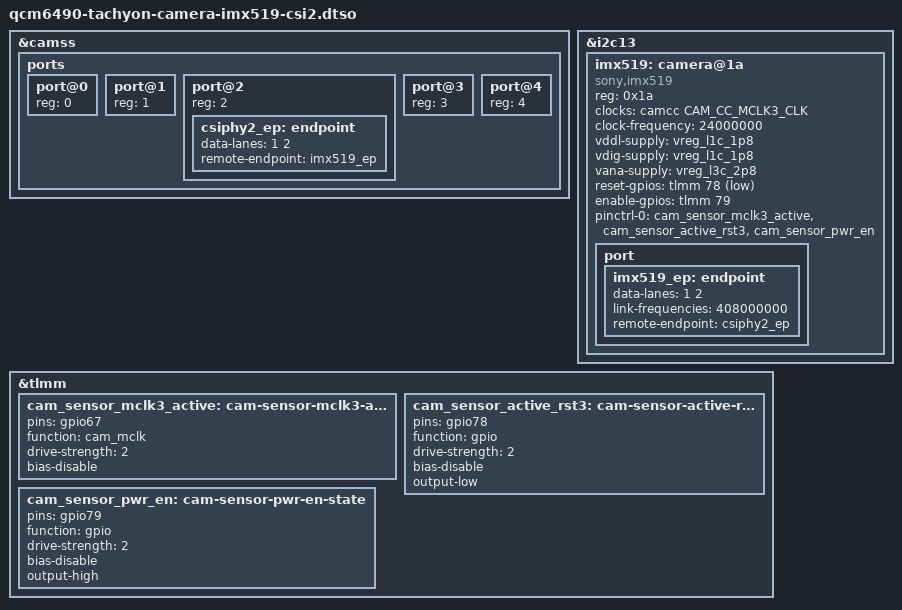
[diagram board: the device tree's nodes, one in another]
// SPDX-License-Identifier: BSD-3-Clause
/*
 * Copyright (c) 2025 Particle Industries, Inc. All rights reserved.
 */

/dts-v1/;
/plugin/;

#include <dt-bindings/gpio/gpio.h>
#include <dt-bindings/clock/qcom,camcc-sc7280.h>

&camss {
	ports {
		#address-cells = <1>;
		#size-cells = <0>;

		// CSIPHY0 - Reserved for primary camera
		port@0 {
			reg = <0>;
		};

		// CSIPHY1 - Shared with DSI
		port@1 {
			reg = <1>;
		};

		// CSIPHY2 - IMX519 camera on dedicated CSI2 port
		port@2 {
			reg = <2>;
			csiphy2_ep: endpoint {
				data-lanes = <1 2>;
				remote-endpoint = <&imx519_ep>;
			};
		};

		// CSIPHY3-4 - Available for future use
		port@3 {
			reg = <3>;
		};

		port@4 {
			reg = <4>;
		};
	};
};

// I2C bus for camera sensors - using I2C13 (CSI/DSI I2C Bus)
&i2c13 {
	#address-cells = <1>;
	#size-cells = <0>;

	imx519: camera@1a {
		compatible = "sony,imx519";
		reg = <0x1a>;

		clocks = <&camcc CAM_CC_MCLK3_CLK>;
		clock-names = "xclk";
		clock-frequency = <24000000>;

		vddl-supply = <&vreg_l1c_1p8>;   // 1.8V digital I/O
		vdig-supply = <&vreg_l1c_1p8>;    // 1.05V digital core (using 1.8V rail)
		vana-supply = <&vreg_l3c_2p8>;    // 2.8V analog

		reset-gpios = <&tlmm 78 GPIO_ACTIVE_LOW>;    // Reset on GPIO78
		enable-gpios = <&tlmm 79 GPIO_ACTIVE_HIGH>;  // Power enable on GPIO79

		pinctrl-names = "default";
		pinctrl-0 = <&cam_sensor_mclk3_active &cam_sensor_active_rst3 &cam_sensor_pwr_en>;

		port {
			imx519_ep: endpoint {
				data-lanes = <1 2>;
				link-frequencies = /bits/ 64 <408000000>;
				remote-endpoint = <&csiphy2_ep>;
			};
		};
	};
};

&tlmm {
	cam_sensor_mclk3_active: cam-sensor-mclk3-active-state {
		pins = "gpio67";
		function = "cam_mclk";
		drive-strength = <2>;
		bias-disable;
	};

	cam_sensor_active_rst3: cam-sensor-active-rst3-state {
		pins = "gpio78";
		function = "gpio";
		drive-strength = <2>;
		bias-disable;
		output-low;
	};

	cam_sensor_pwr_en: cam-sensor-pwr-en-state {
		pins = "gpio79";
		function = "gpio";
		drive-strength = <2>;
		bias-disable;
		output-high;
	};
};
